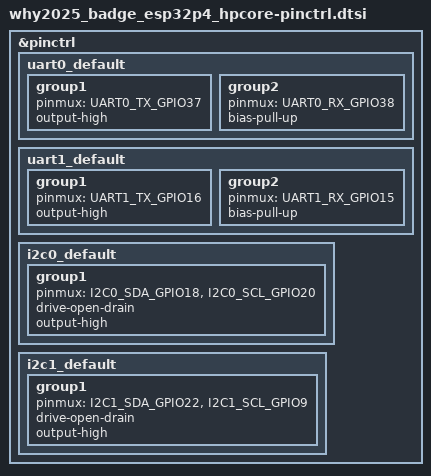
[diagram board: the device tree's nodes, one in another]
/*
 * SPDX-FileCopyrightText: Copyright The Zephyr Project Contributors
 * SPDX-License-Identifier: Apache-2.0
 */

#include <zephyr/dt-bindings/pinctrl/esp-pinctrl-common.h>
#include <zephyr/dt-bindings/pinctrl/esp32p4-pinctrl.h>
#include <zephyr/dt-bindings/pinctrl/esp32p4-gpio-sigmap.h>

&pinctrl {
	/* CH340K USB-UART bridge on the compute module */
	uart0_default: uart0_default {
		group1 {
			pinmux = <UART0_TX_GPIO37>;
			output-high;
		};

		group2 {
			pinmux = <UART0_RX_GPIO38>;
			bias-pull-up;
		};
	};

	/* UART0 of the ESP32-C6 */
	uart1_default: uart1_default {
		group1 {
			pinmux = <UART1_TX_GPIO16>;
			output-high;
		};

		group2 {
			pinmux = <UART1_RX_GPIO15>;
			bias-pull-up;
		};
	};

	/* Keyboard, environmental sensor, IMU; external pull-ups */
	i2c0_default: i2c0_default {
		group1 {
			pinmux = <I2C0_SDA_GPIO18>, <I2C0_SCL_GPIO20>;
			drive-open-drain;
			output-high;
		};
	};

	/* Add-on header J7; external pull-ups */
	i2c1_default: i2c1_default {
		group1 {
			pinmux = <I2C1_SDA_GPIO22>, <I2C1_SCL_GPIO9>;
			drive-open-drain;
			output-high;
		};
	};
};
